AUTOSAR XML (schema 4-2-1)
package /COM/VECTOR/CFG/WORKFLOW/SYSDESC/SYNC
  system SYSTEM
    system mapping MAPPINGS
      data-mappings:
        data-element=COMPOSITIONTYPE.PpSteeringWheelPosition.DeSteeringWheelPosition, system-signal=sig_SteeringWheelPosition
        data-element=CpSaRightFrontlight.COMPOSITIONTYPE.PpLightPositionOut.DeLightPosition, system-signal=sig_RightHAngle
        data-element=CpSaLeftFrontlight.COMPOSITIONTYPE.PpLightPositionOut.DeLightPosition, system-signal=sig_LeftHAngle
        data-element=COMPOSITIONTYPE.PpRightLightPositionOut.DeLightPosition, system-signal=sig_RightHAngle
        data-element=COMPOSITIONTYPE.PpLeftLightPositionOut.DeLightPosition, system-signal=sig_LeftHAngle
        data-element=COMPOSITIONTYPE.PpLeftLightPositionOut.DeLightLength, system-signal=sig_LeftLightLength
        data-element=COMPOSITIONTYPE.PpRightLightPositionOut.DeLightLength, system-signal=sig_RightLightLength
    root-software-compositions:
      root sw composition prototype COMPOSITIONTYPE: flat-map=FLATMAP, software-composition=COMPOSITIONTYPE
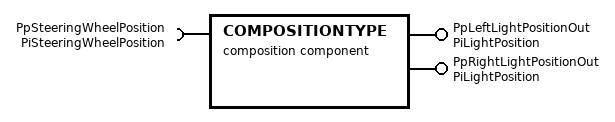
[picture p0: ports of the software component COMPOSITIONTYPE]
  composition sw component type COMPOSITIONTYPE
    require port PpSteeringWheelPosition: nonqueued-receiver-com-spec{data-element=DeSteeringWheelPosition, filter=data-filter-type=ALWAYS, init-value=constant-reference=CSteeringWheelInitPosition}, required-interface=PiSteeringWheelPosition
    provide port PpLeftLightPositionOut: provided-com-specs=[data-element=DeLightLength, {data-element=DeLightPosition, init-value=0}], provided-interface=PiLightPosition
    provide port PpRightLightPositionOut: provided-com-specs=[data-element=DeLightLength, {data-element=DeLightPosition, init-value=0}], provided-interface=PiLightPosition
    12 x component:
      Dem: type=Dem
      Det: type=Det
      EcuM: type=EcuM
      NvM: type=NvM
      ComM: type=ComM
      BswM: type=BswM
      Dcm: type=Dcm
      CpSaSteeringWheel: type=CtSaSteeringWheel
      CpSaLeftFrontlight: type=CtSaFrontlight
      CpCddIoHwAb: type=CtCddIoHwAb
      CpApAFSController: type=CtApAFSController
      CpSaRightFrontlight: type=CtSaFrontlight
    connect BswM.Switch_ESH_ModeSwitch -> BswM.Notification_ESH_ModeNotification
    connect CpApAFSController.PpLightPositionLeft -> CpSaLeftFrontlight.PpLightPositionIn
    connect CpApAFSController.PpLightPositionRight -> CpSaRightFrontlight.PpLightPositionIn
    delegate CpSaSteeringWheel.PpSteeringWheelPositionIn <-> outer port PpSteeringWheelPosition
    delegate CpSaRightFrontlight.PpLightPositionOut <-> outer port PpRightLightPositionOut
    delegate CpSaLeftFrontlight.PpLightPositionOut <-> outer port PpLeftLightPositionOut
    connect CpSaSteeringWheel.PpSteeringWheelPositionOut -> CpApAFSController.PpSteeringWheelPosition
    connect CpCddIoHwAb.PpAFSSwitch -> CpApAFSController.PpAFSSwitch
    connect CpCddIoHwAb.PpHighBeam -> CpApAFSController.PpHighBeam
    connect CpApAFSController.DataServices_Diag_RDI_BatteryValue_BatteryValue -> Dcm.DataServices_Diag_RDI_BatteryValue_BatteryValue
    connect CpApAFSController.DataServices_Diag_RWDI_PassingLane_PassingLane_PassingLane -> Dcm.DataServices_Diag_RWDI_PassingLane_PassingLane_PassingLane
  end to end protection set E2EPROTECTIONSET
  port interface mapping set PORTINTERFACEMAPPINGSET
